# AVR16LA28 register map
Vendor: Atmel; File version: 1.0
CPU: other r0p0, little endian, no MPU, no FPU, 4 interrupt priority bits
Registers are 8-bit, read-write, reset 0x0 unless marked. A register's access mark holds for its fields unless they carry their own. Offsets are from the block's base; [hi:lo] are bit positions.

## CLKCTRL — Clock controller
Base 0x00800060
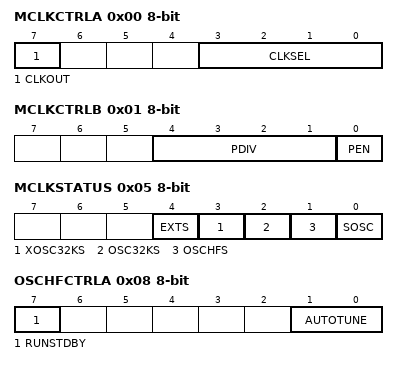
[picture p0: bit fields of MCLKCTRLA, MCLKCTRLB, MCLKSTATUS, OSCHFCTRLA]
0x00 MCLKCTRLA — MCLK Control A
  [7] CLKOUT — System clock out
  [3:0] CLKSEL — Clock select
    0=OSCHF (Internal high-frequency oscillator); 1=OSC32K (Internal 32.768 kHz oscillator); 2=XOSC32K (32.768 kHz crystal oscillator); 3=EXTCLK (External clock)
0x01 MCLKCTRLB — MCLK Control B
  [4:1] PDIV — Prescaler division
    0=DIV2 (Divide by 2); 1=DIV4 (Divide by 4); 2=DIV8 (Divide by 8); 3=DIV16 (Divide by 16); 4=DIV32 (Divide by 32); 5=DIV64 (Divide by 64); 8=DIV6 (Divide by 6); 9=DIV10 (Divide by 10); 10=DIV12 (Divide by 12); 11=DIV24 (Divide by 24); 12=DIV48 (Divide by 48)
  [0] PEN — Prescaler enable
0x05 MCLKSTATUS ro
  [4] EXTS — External Clock status
  [3] XOSC32KS — 32.768 kHz Crystal Oscillator Status
  [2] OSC32KS — 32KHz Oscillator Status
  [1] OSCHFS — High Frequency Oscillator Status
  [0] SOSC — System Oscillator Changing
0x06 MCLKTIMEBASE
  [4:0] TIMEBASE
0x08 OSCHFCTRLA — OSCHF Control A
  [7] RUNSTDBY — Run in standby
  [1:0] AUTOTUNE — Automatic Oscillator Tune
    0=OFF (Disabled); 1=XOSC32K (Tune against 32.768 kHz Crystal Oscillator)
0x09 OSCHFTUNE
  [7:0] TUNE — Oscillator Tune
0x18 OSC32KCTRLA — OSC32K Control A
  [7] RUNSTDBY — Run in Standby Mode
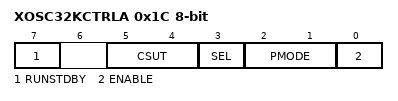
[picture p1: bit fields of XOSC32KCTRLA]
0x1C XOSC32KCTRLA — XOSC32K Control A
  [7] RUNSTDBY — Run in Standby Mode
  [5:4] CSUT — Crystal Oscillator Start-up Time
    0=1K (1k cycles); 1=16K (16k cycles); 2=32K (32k cycles); 3=64K (64k cycles)
  [3] SEL — Source Select
    0=XTAL (External Crystal connected to the XTAL32K1 and XTAL32K2 pins); 1=EXTCLK (External Clock on XTAL32K1 pin)
  [2:1] PMODE — Power Mode
    0=LOW (Low Power Mode (Typ CL=8pF, ESR=50 kOhm)); 1=MEDIUM (Medium Power Mode (Typ CL=12.5pF, ESR=70 kOhm)); 2=HIGH (High Power Mode (Up to CL=24pF, ESR=100 kOhm))
  [0] ENABLE

## CPU
Base 0x00800030
0x00 SPLIM 16-bit (reset mask 0xFF) — Stack Pointer Limit
0x04 CCP — Configuration Change Protection
  [7:0] CCP — CCP signature
    157=SPM (SPM Instruction Protection); 216=IOREG (IO Register Protection)
0x05 CTRLA — Control A
  [0] SPLOCK — SPLIM Lock
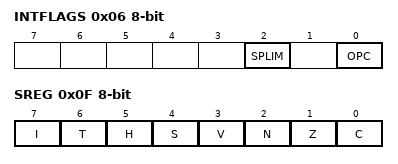
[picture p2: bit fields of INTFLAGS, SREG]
0x06 INTFLAGS — Interrupt Flags
  [2] SPLIM — Stack Pointer Limit Error
  [0] OPC — Illegal Opcode Error
0x0D SP 16-bit (reset mask 0xFF) — Stack Pointer
0x0F SREG — Status Register
  [7] I — Global Interrupt Enable Flag
  [6] T — Transfer Bit
  [5] H — Half Carry Flag
  [4] S — N Exclusive Or V Flag
  [3] V — Two's Complement Overflow Flag
  [2] N — Negative Flag
  [1] Z — Zero Flag
  [0] C — Carry Flag

## CPUINT — Interrupt Controller
Base 0x00800110
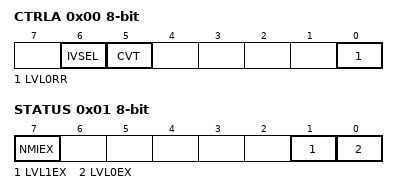
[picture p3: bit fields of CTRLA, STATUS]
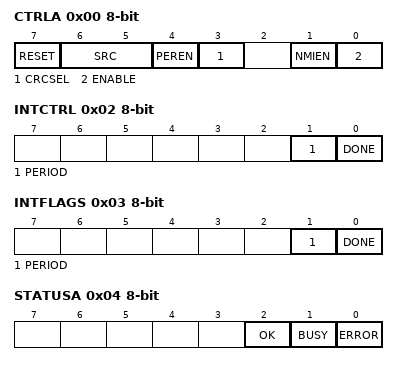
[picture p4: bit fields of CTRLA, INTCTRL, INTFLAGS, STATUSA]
0x00 CTRLA — Control A
  [6] IVSEL — Interrupt Vector Select
  [5] CVT — Compact Vector Table
  [0] LVL0RR — Round-robin Scheduling Enable
0x01 STATUS ro
  [7] NMIEX — Non-maskable Interrupt Executing
  [1] LVL1EX — Level 1 Interrupt Executing
  [0] LVL0EX — Level 0 Interrupt Executing
0x02 LVL0PRI — Interrupt Level 0 Priority
  [7:0] LVL0PRI — Interrupt Level Priority
0x03 LVL1VEC — Interrupt Level 1 Priority Vector
  [7:0] LVL1VEC — Interrupt Vector with High Priority

## CRCSCAN
Base 0x00800120
0x00 CTRLA — Control A
  [7] RESET — Reset CRCSCAN
  [6:5] SRC — CRC Source
    0=BOOT (The CRC is performed on the boot section of Flash); 1=CODE (The CRC is performed on the application code section of Flash); 2=DATA (The CRC is performed on the application data section of Flash); 3=MANUAL (Manual mode, CRC is performed on data written to DATA)
  [4] PEREN — Enable Periodic Timer
    0=DISABLE (The periodic timer is disabled); 1=ENABLE (The periodic timer is enabled)
  [3] CRCSEL — CRC Mode Select
    0=CRC16 (The CRC is performed using CRC16); 1=CRC32 (The CRC is performed using CRC32)
  [1] NMIEN — Enable NMI Trigger
  [0] ENABLE — Enable CRCSCAN
0x01 CTRLB wo — Control B
  [0] EINJ — Inject CRC error
0x02 INTCTRL — Interrupt Control
  [1] PERIOD — Scan Period Done Interrupt Enable
  [0] DONE — Scan Done Interrupt Enable
0x03 INTFLAGS — Interrupt Flags
  [1] PERIOD — Scan Period Done
  [0] DONE — Scan Done
0x04 STATUSA ro
  [2] OK — CRC OK
  [1] BUSY — CRC BUSY
  [0] ERROR — Error Signal driving NMI
0x05 SCANADR ro — Scan Address
  [7:0] SCANADR — Address Being Scanned
0x06 DATA wo — Input Data
0x08 CRC 32-bit ro (reset mask 0xFF) — CRC Result
